# LKS32MC07x register map
Vendor: Linko Ltd.; Series: LKS32MC07x; File version: 1.0
CPU: CM0 r1p0, little endian, MPU, no FPU, 3 interrupt priority bits
Registers are 32-bit, read-write, reset 0x0 unless marked. A register's access mark holds for its fields unless they carry their own. Offsets are from the block's base; [hi:lo] are bit positions; {n}, {i} and the like mark numbered series.

## EXTI — EXTI registers
Base 0x40010E00
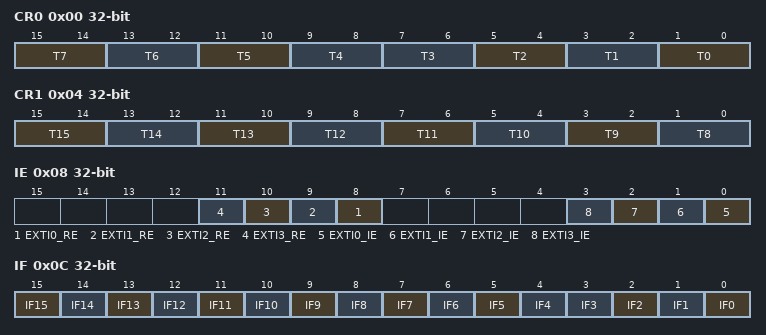
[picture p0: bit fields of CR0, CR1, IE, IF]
0x00 CR0 — GPIO external interrupt trigger type 0
  [15:14] T7 — GPIO0[15] external interrupt trigger type
  [13:12] T6 — GPIO0[14] external interrupt trigger type
  [11:10] T5 — GPIO0[11] external interrupt trigger type
  [9:8] T4 — GPIO0[6] external interrupt trigger type
  [2n+1:2n] T{n} (n=0..3) — GPIO0[{n}] external interrupt trigger type
0x04 CR1 — GPIO external interrupt trigger type 1
  [15:14] T15 — GPIO2[15] external interrupt trigger type
  [13:12] T14 — GPIO2[12] external interrupt trigger type
  [11:10] T13 — GPIO2[7] external interrupt trigger type
  [9:8] T12 — GPIO2[4] external interrupt trigger type
  [7:6] T11 — GPIO2[3] external interrupt trigger type
  [5:4] T10 — GPIO1[10] external interrupt trigger type
  [3:2] T9 — GPIO1[1] external interrupt trigger type
  [1:0] T8 — GPIO1[0] external interrupt trigger type
0x08 IE (reset mask 0x303) — GPIO interrupt enable
  [n+8] EXTI{n}_RE (n=0..3) — GPIO{n} DMA enable
  [n] EXTI{n}_IE (n=0..3) — GPIO{n} interrupt enable
0x0C IF — GPIO interrupt flag
  [15] IF15 — GPIO2[15] interrupt flag
  [14] IF14 — GPIO2[12] interrupt flag
  [13] IF13 — GPIO2[7] interrupt flag
  [12] IF12 — GPIO2[5] interrupt flag
  [11] IF11 — GPIO2[4] interrupt flag
  [10] IF10 — GPIO1[10] interrupt flag
  [9] IF9 — GPIO1[1] interrupt flag
  [8] IF8 — GPIO1[0] interrupt flag
  [7] IF7 — GPIO0[15] interrupt flag
  [6] IF6 — GPIO0[14] interrupt flag
  [5] IF5 — GPIO0[11] interrupt flag
  [4] IF4 — GPIO0[6] interrupt flag
  [n] IF{n} (n=0..3) — GPIO0[{n}] interrupt flag
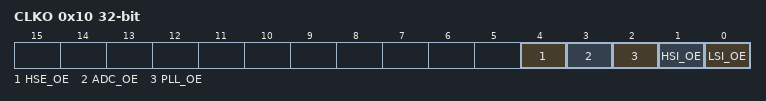
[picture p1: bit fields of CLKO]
0x10 CLKO (reset mask 0xF) — GPIO output clock selection
  [4] HSE_OE — Xtal Clock output enable
  [3] ADC_OE — ADC Clock output enable
  [2] PLL_OE — PLL Clock output enable
  [1] HSI_OE — HSI Clock output enable
  [0] LSI_OE — LSI Clock output enable
0x14 PWM_SW — MCPWM Swap Option
  [1:0] SWAP — MCPWM swap option

## CRC0 — CRC0 registers
Base 0x40010F00
0x00 DR — CRC data
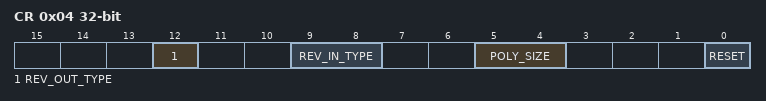
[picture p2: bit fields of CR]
0x04 CR — CRC control
  [12] REV_OUT_TYPE — output reversed
  [9:8] REV_IN_TYPE — input reversed
    0=NO_REV (no reverse); 1=BYTE_REV (byte reversed); 2=HALFWORD_REV (halfword reversed); 3=WORD_REV (word reversed)
  [5:4] POLY_SIZE — crc result output bit width
    0=32BITS; 1=16BITS; 2=8BITS; 3=7BITS
  [0] RESET wo — reset crc chain to use CRC_INIT as initial value in crc calculation
    0=LAST (Use last crc result as crc initial value); 1=INIT (Use CRC_INIT as crc initial value)
0x08 INIT reset 0xFFFFFFFF — CRC initial value
0x0C POL — CRC coefficient

## UART0 — UART0 registers
Base 0x40011000
Same registers: UART1 0x40011100
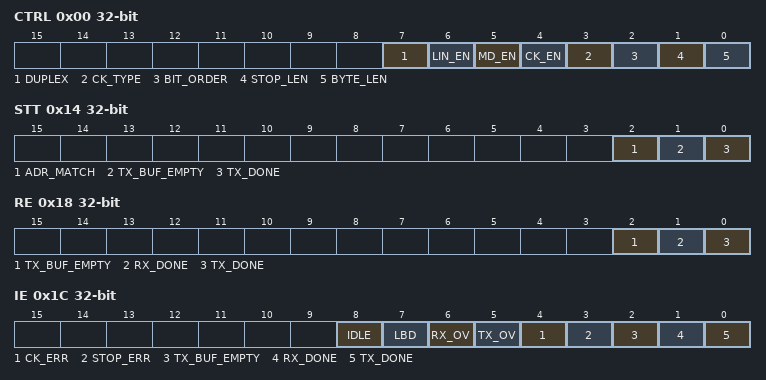
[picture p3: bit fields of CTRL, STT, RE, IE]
0x00 CTRL — UART control
  [7] DUPLEX — Duplex mode enable
    0=Disabled (Duplex mode is disabled); 1=Enabled (Duplex mode is enabled)
  [6] LIN_EN — LIN mode enable
    0=Disabled (LIN mode is disabled); 1=Enabled (LIN mode is enabled)
  [5] MD_EN — Multi-drop mode enable
    0=Disabled (Multi-drop mode disabled); 1=Enabled (Multi-drop mode enabled)
  [4] CK_EN — Odd-Even Check enable
    0=Disabled (Odd-Even check disabled); 1=Enabled (Odd-Even check enabled)
  [3] CK_TYPE — Odd or Even Check
    0=EVEN (Even check); 1=ODD (Odd check)
  [2] BIT_ORDER — LSB or MSB
    0=LSB; 1=MSB
  [1] STOP_LEN — Stop bit length
    0=1B (1bit stop bit); 1=2B (2bit stop bit)
  [0] BYTE_LEN — Byte length
    0=8B (8bit per byte); 1=9B (9bit per byte)
0x04 DIVH — UART Baudrate higher byte
  [7:0] DIVH
0x08 DIVL — UART Baudrate lower byte
  [7:0] DIVL
0x0C BUFF — UART read/write buffer
  [8:0] BUFF
0x10 ADR — UART match address
  [7:0] ADR
0x14 STT — UART status
  [2] ADR_MATCH — Address matched in multi-drop mode
  [1] TX_BUF_EMPTY — TX Buffer empty
  [0] TX_DONE — Transmission fnished
0x18 RE — UART dma request enable
  [2] TX_BUF_EMPTY — TX Buffer empty DMA request enable
  [1] RX_DONE — Byte received DMA request enable
  [0] TX_DONE — Byte transmission finished DMA request flag
0x1C IE — UART interrrupt enable
  [8] IDLE — Idle frame detection interrupt enable
  [7] LBD — LIN break character detection interrupt enable
  [6] RX_OV — RX overflow interrupt enable
  [5] TX_OV — TX overflow interrupt enable
  [4] CK_ERR — Check error interrupt enable
  [3] STOP_ERR — Stop bit error interrupt enable
  [2] TX_BUF_EMPTY — TX Buffer empty interrupt enable
  [1] RX_DONE — Byte received interrupt enable
  [0] TX_DONE — Byte transmission finished interrupt flag
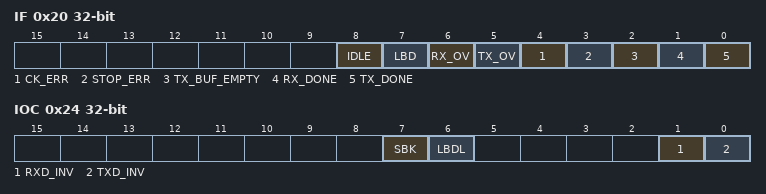
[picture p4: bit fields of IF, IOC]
0x20 IF — UART interrupt flag
  [8] IDLE — Idle frame detection interrupt flag
  [7] LBD — LIN break character detection interrupt flag
  [6] RX_OV — RX overflow interrupt flag
  [5] TX_OV — TX overflow interrupt flag
  [4] CK_ERR — Check error interrupt flag
  [3] STOP_ERR — Stop bit error interrupt flag
  [2] TX_BUF_EMPTY — TX Buffer empty interrupt flag
  [1] RX_DONE — Byte received interrupt flag
  [0] TX_DONE — Byte transmission finished interrupt flag
0x24 IOC — UART IO Control
  [7] SBK — Send break character in LIN mode
  [6] LBDL — break character length in LIN mode
  [1] RXD_INV — RXD inverted then input
  [0] TXD_INV — TXD inverted then output
